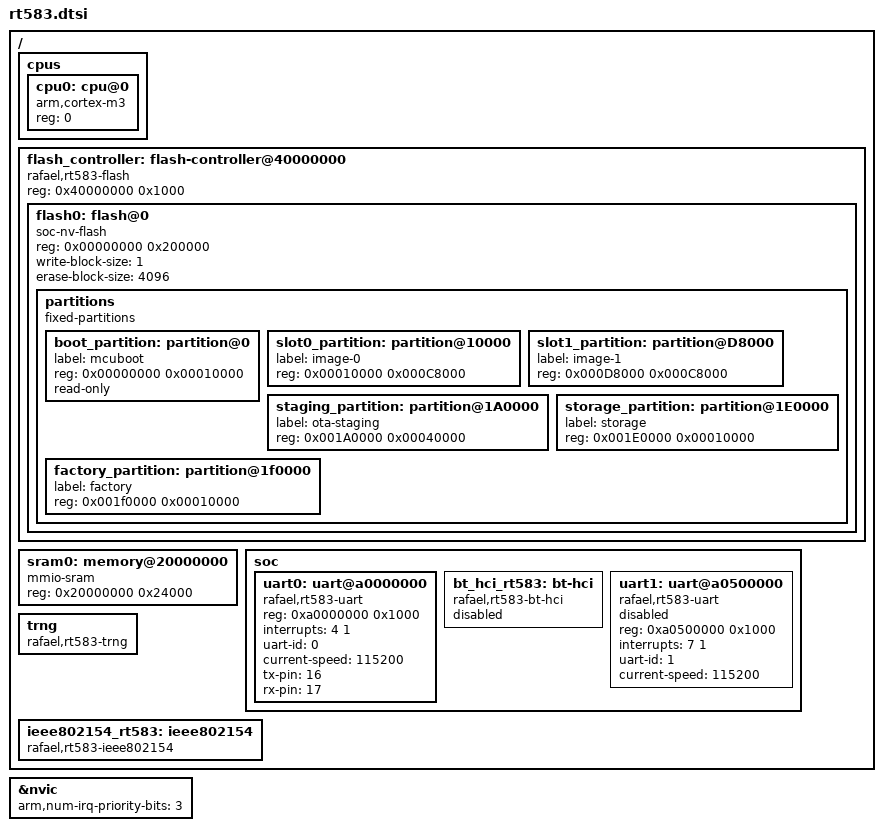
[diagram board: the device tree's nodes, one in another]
/*
 * RT583 SoC device tree include (ARM Cortex-M3)
 *
 * Memory map sourced from:
 *   components/platform/soc/rt583/rt583_driver/Inc/mcu.h
 *   components/platform/soc/rt583/rt583_evb/evb/ld/rt583.ld
 *
 * PERIPH_BASE  = 0x40000000
 * PERIPH_BASE2 = 0xA0000000  (UART, COMM_SUBSYSTEM)
 *
 * IRQ numbers (from mcu.h IRQn_Type enum):
 *   Uart0_IRQn = 4
 *   Uart1_IRQn = 7
 *   Uart2_IRQn = 19
 */

#include <arm/armv7-m.dtsi>

/ {
    cpus {
        #address-cells = <1>;
        #size-cells = <0>;

        cpu0: cpu@0 {
            compatible = "arm,cortex-m3";
            reg = <0>;
        };
    };

    /*
     * RT583 flash layout (from rt583.ld LMA regions):
     *   0x00000000  BOOT  32 KB   (bootloader)
     *   0x00008000  CORE  928 KB  (main application)
     *   0x000F0000  USER  32 KB
     *   0x000F0800  MP    32 KB
     *
     * For a standalone Zephyr image we occupy the full 1 MB.
     */
    flash_controller: flash-controller@40000000 {
        compatible = "rafael,rt583-flash";
        reg = <0x40000000 0x1000>;
        #address-cells = <1>;
        #size-cells = <1>;

        flash0: flash@0 {
            compatible = "soc-nv-flash";
            reg = <0x00000000 0x200000>;    /* 2 MB */
            write-block-size = <1>;
            erase-block-size = <4096>;

            partitions {
                compatible = "fixed-partitions";
                #address-cells = <1>;
                #size-cells = <1>;

                /*
                 * Direct XIP layout (2 MB flash):
                 *
                 *   0x000000  boot       64 KB  MCUboot
                 *   0x010000  slot0     800 KB  App primary   (Direct XIP)
                 *   0x0D8000  slot1     800 KB  App secondary (Direct XIP)
                 *   0x1A0000  staging   256 KB  OTA compressed download buffer
                 *   0x1E0000  storage    64 KB  NVS / OpenThread dataset
                 *   0x1F0000  factory    64 KB  MP sector / factory data
                 *
                 * Slot size 800 KB; fits Matter lighting (~794 KB).
                 * MCUboot selects the newest valid image and jumps directly —
                 * no swap, no copy to RAM.
                 * Slot 0 and Slot 1 must be identical size.
                 */

                /* MCUboot bootloader: 64 KB */
                boot_partition: partition@0 {
                    label = "mcuboot";
                    reg = <0x00000000 0x00010000>;
                    read-only;
                };

                /* Primary image slot: 800 KB */
                slot0_partition: partition@10000 {
                    label = "image-0";
                    reg = <0x00010000 0x000C8000>;
                };

                /* Secondary image slot: 800 KB (Direct XIP — equal to slot 0) */
                slot1_partition: partition@D8000 {
                    label = "image-1";
                    reg = <0x000D8000 0x000C8000>;
                };

                /* OTA compressed image staging: 256 KB
                 * Receives LZ4-compressed image before decompressing to slot1. */
                staging_partition: partition@1A0000 {
                    label = "ota-staging";
                    reg = <0x001A0000 0x00040000>;
                };

                /* NV storage (OpenThread settings, Zephyr NVS): 64 KB */
                storage_partition: partition@1E0000 {
                    label = "storage";
                    reg = <0x001E0000 0x00010000>;
                };

                /* MP sector + factory data: 64 KB (flash 末段) */
                factory_partition: partition@1f0000 {
                    label = "factory";
                    reg = <0x001f0000 0x00010000>;
                };
            };
        };
    };

    sram0: memory@20000000 {
        compatible = "mmio-sram";
        /* 144 KB = 0x24000 (from VMA_DATA + VMA_STACK in rt583.ld) */
        reg = <0x20000000 0x24000>;
    };

    soc {
        /*
         * UART0 – stdio console
         *   Base : PERIPH_BASE2        = 0xA0000000
         *   IRQ  : Uart0_IRQn         = 4
         *   Pins : TX=GPIO16, RX=GPIO17 (from default-rt583-evb.config)
         *   Baud : 115200
         */
        uart0: uart@a0000000 {
            compatible = "rafael,rt583-uart";
            reg = <0xa0000000 0x1000>;
            interrupts = <4 1>;
            uart-id = <0>;
            current-speed = <115200>;
            tx-pin = <16>;
            rx-pin = <17>;
            status = "okay";
        };

        /*
         * UART1
         *   Base : PERIPH_BASE2 + 0x500000 = 0xA0500000
         *   IRQ  : Uart1_IRQn = 7
         */
        bt_hci_rt583: bt-hci {
            compatible = "rafael,rt583-bt-hci";
            status = "disabled";
        };

        uart1: uart@a0500000 {
            compatible = "rafael,rt583-uart";
            reg = <0xa0500000 0x1000>;
            interrupts = <7 1>;
            uart-id = <1>;
            current-speed = <115200>;
            status = "disabled";
        };
    };
};

/* RT583 hardware TRNG — no memory-mapped register; accessed via HOSAL. */
/* RT583 IEEE 802.15.4 radio — accessed via lmac15p4 library, not MMIO. */
/ {
    trng: trng {
        compatible = "rafael,rt583-trng";
        status = "okay";
    };

    ieee802154_rt583: ieee802154 {
        compatible = "rafael,rt583-ieee802154";
        status = "okay";
    };
};

/* RT583 Cortex-M3 NVIC: 3 priority bits (__NVIC_PRIO_BITS = 3 in mcu.h) */
&nvic {
    arm,num-irq-priority-bits = <3>;
};

/* Point the Zephyr console at UART0. */
&uart0 {
    status = "okay";
};
